# RS1xxxx register map
Vendor: Silicon Lab Inc.; Series: ARMCM4; File version: 1.2
CPU: CM4 r1p0, little endian, MPU, FPU, 6 interrupt priority bits
Registers are 32-bit, read-write, reset 0x0 unless marked. A register's access mark holds for its fields unless they carry their own. Offsets are from the block's base; [hi:lo] are bit positions; 'fields as' and 'values as' point back to an identical list.

## IID_RPINE
Base 0x20480400
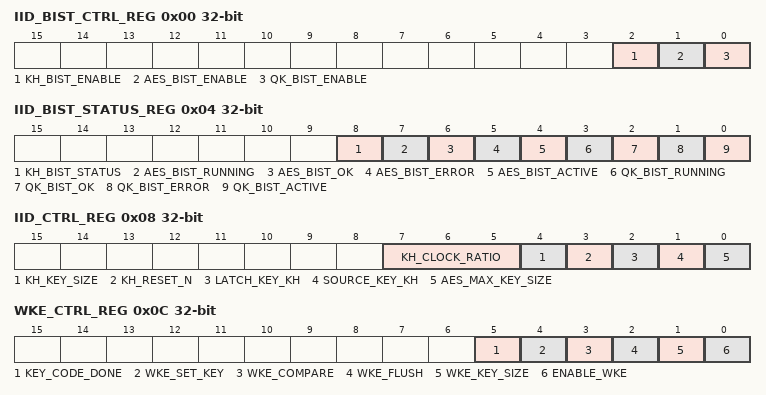
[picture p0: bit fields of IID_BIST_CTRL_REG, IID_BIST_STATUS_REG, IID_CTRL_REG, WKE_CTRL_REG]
0x00 IID_BIST_CTRL_REG — Quiddikey Control register.The Quiddikey Control register defines which command must be executed next.
  [2] KH_BIST_ENABLE, [1] AES_BIST_ENABLE, [0] QK_BIST_ENABLE
0x04 IID_BIST_STATUS_REG
  [8] KH_BIST_STATUS
  [7] AES_BIST_RUNNING — Indicates that the BIST is running
  [6] AES_BIST_OK — Indicates that the BIST has passed
  [5] AES_BIST_ERROR
  [4] AES_BIST_ACTIVE
  [3] QK_BIST_RUNNING — Indicates that the BIST is running
  [2] QK_BIST_OK — Indicates that the BIST has passed
  [1] QK_BIST_ERROR — Indicates that the BIST has failed
  [0] QK_BIST_ACTIVE
0x08 IID_CTRL_REG
  [7:5] KH_CLOCK_RATIO — Indicates the division factor to be used for generating kh_clk.
  [4] KH_KEY_SIZE — 0 128 bit key 1 256 bit key This is used by KH
  [3] KH_RESET_N — 0 KH will be in reset 1 Out of reset
  [2] LATCH_KEY_KH — When set KH will latch the key given by QK. When this is not QK key output is connected to AES key input
  [1] SOURCE_KEY_KH — When set KH will source the key to AES engine. When this is not QK key output is connected to AES key input
  [0] AES_MAX_KEY_SIZE — 1 256 bit key, 0 128 bit key
0x0C WKE_CTRL_REG
  [5] KEY_CODE_DONE — This has to be set after reading key code
  [4] WKE_SET_KEY — This has to be set after key available from AES
  [3] WKE_COMPARE — When set, WKE will compare the data from AES engine with the data provided by firmware
  [2] WKE_FLUSH — When set, WKE will flush out the data from AES. When WEK is active, firmware reads to AES engine are masked. This gets cleared once four dwords are read from AES
  [1] WKE_KEY_SIZE — 0 128 bit size 1 256 bit size
  [0] ENABLE_WKE — When WKE will be enabled. This is a self clearing bit. Once enabled WKE can not be disabled till process is done
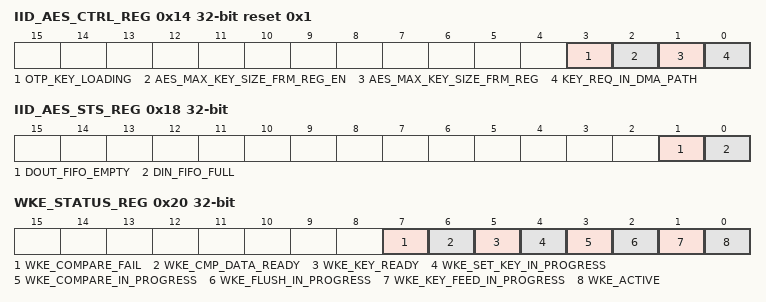
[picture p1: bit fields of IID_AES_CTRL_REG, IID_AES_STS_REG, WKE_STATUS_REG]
0x14 IID_AES_CTRL_REG reset 0x1
  [3] OTP_KEY_LOADING — When set, WKE will compare the data from AES engine with the data provided by firmware
    1=Enable (Loads the OTP Key into the AES Engine, before setting this bit, key should be read from the OTP by reading the otp registers, more information please refer the otp section); 0=Disable (OTP Key will not be loaded)
  [2] AES_MAX_KEY_SIZE_FRM_REG_EN — When set, WKE will flush out the data from AES. When WEK is active, firmware reads to AES engine are masked. This gets cleared once four dwords are read from AES
    1=Enable (AES bit length prog enable.); 0=Disable (AES bit length prog disable.)
  [1] AES_MAX_KEY_SIZE_FRM_REG — This is valid only when aes_max_key_size_frm_reg_en is set.
  [0] KEY_REQ_IN_DMA_PATH — Include key req in dma path. With this KEY Also can be loaded using DMA.
0x18 IID_AES_STS_REG ro
  [1] DOUT_FIFO_EMPTY — Output data fifo empty indication
  [0] DIN_FIFO_FULL — Input data fifo full indication
0x20 WKE_STATUS_REG
  [7] WKE_COMPARE_FAIL — This bit will be set when authentication data comparison fails
  [6] WKE_CMP_DATA_READY — Firmware has to load the authentication, which will be compared with AES output, when this bit is low
  [5] WKE_KEY_READY — Firmware has to load the authentication, which will be compared with AES output, when this bit is low
  [4] WKE_SET_KEY_IN_PROGRESS — Will be high when WKE is doing set key operation with QK
  [3] WKE_COMPARE_IN_PROGRESS — Will be high when WKE is comparing the data from AES
  [2] WKE_FLUSH_IN_PROGRESS — Will be high when WKE flushing out the data from AES
  [1] WKE_KEY_FEED_IN_PROGRESS — Will be high when WKE is feeding key to AES engine
  [0] WKE_ACTIVE — Will be high when WKE is active
0x28 WKE_DATA_REG

## CT_MUX_REG — Configurable timer is used in counting clocks, events and states with reference clock external clock and system clock
Base 0x4506F000
0x00 CT_MUX_SEL_0_REG — MUX_SEL_0_REG Register
  [3:0] MUX_SEL_0 — Select value to select first output value fifo_0_full[0] out of all the fifo_0_full_muxed signals of counter 0
0x04 CT_MUX_SEL_1_REG — MUX_SEL_1_REG Register
  [3:0] MUX_SEL_1 — Select value to select first output value fifo_0_full[1] out of all the fifo_0_full_muxed signals of counter 0
0x08 CT_MUX_SEL_2_REG — MUX_SEL_2_REG Register
  [3:0] MUX_SEL_2 — Select value to select first output value fifo_1_full[0] out of all the fifo_1_full_muxed signals of counter 1
0x0C CT_MUX_SEL_3_REG reset 0xFFFF — MUX_SEL_3_REG Register
  [3:0] MUX_SEL_3 — Select value to select first output value fifo_1_full[1] out of all the fifo_1_full_muxed signals of counter 1
0x18 CT_OUTPUT_EVENT1_ADC_SEL reset 0xFFFF — OUTPUT_EVENT_ADC_SEL Register
  [3:0] OUTPUT_EVENT_ADC_SEL — Select signals to select one output event out of all the output events output_event_0 output_event_1, output_event_2, output_event_3 to enable ADC module
0x1C CT_OUTPUT_EVENT2_ADC_SEL reset 0xFFFF — OUTPUT_EVENT_ADC_SEL Register
  fields as CT_OUTPUT_EVENT1_ADC_SEL
